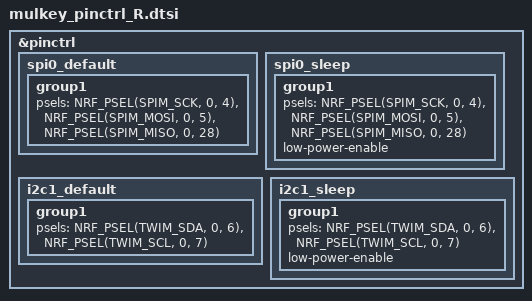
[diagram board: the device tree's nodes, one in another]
&pinctrl {
    /* --- SPIの設定 (既存) --- */
    spi0_default: spi0_default {
        group1 {
            psels = <NRF_PSEL(SPIM_SCK, 0, 4)>,
                    <NRF_PSEL(SPIM_MOSI, 0, 5)>,
                    <NRF_PSEL(SPIM_MISO, 0, 28)>;
        };
    };

    spi0_sleep: spi0_sleep {
        group1 {
            psels = <NRF_PSEL(SPIM_SCK, 0, 4)>,
                    <NRF_PSEL(SPIM_MOSI, 0, 5)>,
                    <NRF_PSEL(SPIM_MISO, 0, 28)>;
            low-power-enable;
        };
    };

    /* --- I2Cの設定 (追加) --- */
    i2c1_default: i2c1_default {
        group1 {
            /* SDA=P0.06, SCL=P0.07 の例 (XIAO BLEの回路図に合わせて調整してください) */
            psels = <NRF_PSEL(TWIM_SDA, 0, 6)>,
                    <NRF_PSEL(TWIM_SCL, 0, 7)>;
        };
    };

    i2c1_sleep: i2c1_sleep {
        group1 {
            psels = <NRF_PSEL(TWIM_SDA, 0, 6)>,
                    <NRF_PSEL(TWIM_SCL, 0, 7)>;
            low-power-enable;
        };
    };
};
